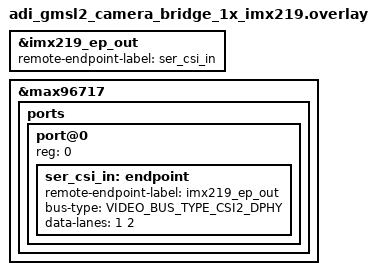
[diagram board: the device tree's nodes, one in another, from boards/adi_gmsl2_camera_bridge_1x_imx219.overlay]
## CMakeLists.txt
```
# SPDX-License-Identifier: Apache-2.0

cmake_minimum_required(VERSION 3.20.0)
find_package(Zephyr REQUIRED HINTS $ENV{ZEPHYR_BASE})
project(adi_gmsl2_camera_bridge)

target_sources(app PRIVATE
  src/main.c
  src/gmsl_diag.c
)
```

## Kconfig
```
# Copyright (c) 2026 Charles Dias
# SPDX-License-Identifier: Apache-2.0

mainmenu "GMSL2 Camera Bridge Sample"

source "Kconfig.zephyr"

module = APP
module-str = Application
source "subsys/logging/Kconfig.template.log_config"
```

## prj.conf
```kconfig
CONFIG_VIDEO=y
CONFIG_LOG=y
CONFIG_PRINTK=y
CONFIG_LOG_BUFFER_SIZE=8192

# CONFIG_VIDEO_FRAME_WIDTH=800
# CONFIG_VIDEO_FRAME_HEIGHT=480
# CONFIG_VIDEO_PIXEL_FORMAT="RGBP"
CONFIG_VIDEO_BUFFER_POOL_HEAP_SIZE=1600000
CONFIG_MAIN_STACK_SIZE=4096


# Remove before merging
CONFIG_APP_LOG_LEVEL_DBG=y
# CONFIG_VIDEO_LOG_LEVEL_DBG=y
```

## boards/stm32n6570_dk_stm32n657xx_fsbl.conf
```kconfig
# IMX219 through GMSL2 — capture + display
# DCMIPP source sensor format (IMX219 native)
CONFIG_VIDEO_STM32_DCMIPP_SENSOR_PIXEL_FORMAT="pBAA"
CONFIG_VIDEO_STM32_DCMIPP_SENSOR_WIDTH=3280
CONFIG_VIDEO_STM32_DCMIPP_SENSOR_HEIGHT=2464

# Deserializer in passthrough mode (not VPG)
CONFIG_VIDEO_MAX96724_VPG_INTERNAL=n
CONFIG_VIDEO_MAX96724_TPG_TOLERATE_NO_LINK=n

# An 800x480 RGB24 frame is 1152000 bytes; double-buffer + slack.
CONFIG_VIDEO_BUFFER_POOL_HEAP_SIZE=2500000

# Render frames on the on-board LTDC display.
CONFIG_DISPLAY=y
CONFIG_STM32_LTDC=y
CONFIG_STM32_LTDC_RGB888=y
```

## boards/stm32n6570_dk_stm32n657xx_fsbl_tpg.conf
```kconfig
# TPG validation mode: MAX96724 internal test pattern → CSI-2 → DCMIPP → display
CONFIG_APP_TPG_MODE=y

# Deserializer runs its own VPG — override the base board conf.
CONFIG_VIDEO_MAX96724_VPG_INTERNAL=y
CONFIG_VIDEO_MAX96724_TPG_TOLERATE_NO_LINK=y

# DCMIPP must be told to expect 800x480 RGB888 from its remote subdevice
# (the MAX96724 in VPG mode). Sized to fill the on-board LTDC panel.
CONFIG_VIDEO_STM32_DCMIPP_SENSOR_PIXEL_FORMAT="BGR3"
CONFIG_VIDEO_STM32_DCMIPP_SENSOR_WIDTH=800
CONFIG_VIDEO_STM32_DCMIPP_SENSOR_HEIGHT=480

# An 800x480 RGB24 frame is 1152000 bytes; double-buffer + slack.
CONFIG_VIDEO_BUFFER_POOL_HEAP_SIZE=2500000

# Render frames on the on-board LTDC display.
CONFIG_DISPLAY=y
CONFIG_STM32_LTDC=y

# The VPG produces RGB24, so size the LTDC framebuffer for 3 bytes/pixel.
# Without this the driver defaults to RGB565 (2 bytes/pixel) and the runtime
# display_set_pixel_format() switch overruns the back buffer.
CONFIG_STM32_LTDC_RGB888=y
```

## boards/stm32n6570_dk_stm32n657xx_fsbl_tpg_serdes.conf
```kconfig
# SerDes loopback validation: MAX96717 PATGEN -> GMSL2 -> MAX96724 passthrough
# -> CSI-2 -> DCMIPP -> display
CONFIG_APP_TPG_MODE=y

# DCMIPP must be told to expect 800x480 RGB888 from its remote subdevice.
CONFIG_VIDEO_STM32_DCMIPP_SENSOR_PIXEL_FORMAT="BGR3"
CONFIG_VIDEO_STM32_DCMIPP_SENSOR_WIDTH=800
CONFIG_VIDEO_STM32_DCMIPP_SENSOR_HEIGHT=480

# An 800x480 RGB24 frame is 1152000 bytes; double-buffer + slack.
CONFIG_VIDEO_BUFFER_POOL_HEAP_SIZE=2500000

# Render frames on the on-board LTDC display.
CONFIG_DISPLAY=y
CONFIG_STM32_LTDC=y
CONFIG_STM32_LTDC_RGB888=y

# Enable the serializer PATGEN as the frame source.
CONFIG_VIDEO_MAX96717=y
CONFIG_VIDEO_MAX96717_PATGEN_ENABLE=y
CONFIG_VIDEO_MAX96717_PATGEN_PATTERN_GRADIENT=y

# Deserializer runs in passthrough mode — no internal VPG.
CONFIG_VIDEO_MAX96724=y
CONFIG_VIDEO_MAX96724_VPG_INTERNAL=n

# The GMSL link must be locked — no tolerance for missing serializer.
CONFIG_VIDEO_MAX96724_TPG_TOLERATE_NO_LINK=n
```

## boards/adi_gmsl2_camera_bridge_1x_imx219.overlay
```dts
/*
 * Copyright (c) 2026 Charles Dias
 *
 * SPDX-License-Identifier: Apache-2.0
 *
 * Wires a single IMX219 camera sensor through the ADI GMSL2 bridge.
 *
 * Overlay merge order:
 *   1. raspberry_pi_camera_module_2 → creates IMX219, wires imx219_ep_out → csi_ep_in
 *   2. adi_gmsl2_camera_bridge      → creates MAX96724 + MAX96717, overrides csi_ep_in
 *   3. This overlay                 → rewires imx219_ep_out → max96717_csi_in
 *
 */

#include <zephyr/dt-bindings/video/video-interfaces.h>

&imx219_ep_out {
	remote-endpoint-label = "ser_csi_in";
};

&max96717 {
	ports {
		port@0 {
			reg = <0>;

			ser_csi_in: endpoint {
				remote-endpoint-label = "imx219_ep_out";
				bus-type = <VIDEO_BUS_TYPE_CSI2_DPHY>;
				data-lanes = <1 2>;
			};
		};
	};
};
```

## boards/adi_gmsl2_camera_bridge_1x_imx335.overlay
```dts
/*
 * Copyright (c) 2026 Charles Dias
 *
 * SPDX-License-Identifier: Apache-2.0
 *
 * Wires a single IMX335 camera sensor through the ADI GMSL2 bridge.
 *
 * Overlay merge order:
 *   1. st_b_cams_imx_mb1854 → creates IMX335, wires imx335_ep_out → csi_ep_in
 *   2. adi_gmsl2_camera_bridge      → creates MAX96724 + MAX96717, overrides csi_ep_in
 *   3. This overlay                 → rewires imx335_ep_out → max96717_csi_in
 *
 */

#include <zephyr/dt-bindings/video/video-interfaces.h>

&imx335_ep_out {
	remote-endpoint-label = "max96717_csi_in";
};

&max96717 {
	ports {
		port@0 {
			reg = <0>;

			max96717_csi_in: endpoint {
				remote-endpoint-label = "imx335_ep_out";
				bus-type = <VIDEO_BUS_TYPE_CSI2_DPHY>;
				data-lanes = <1 2>;
			};
		};
	};
};
```

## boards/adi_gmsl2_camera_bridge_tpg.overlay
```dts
/*
 * Copyright (c) 2026 Charles Dias
 *
 * SPDX-License-Identifier: Apache-2.0
 *
 * MAX96724 Video Pattern Generator (VPG / TPG) validation overlay.
 *
 * This overlay configures the sample to drive the host capture pipeline
 * (DCMIPP -> LTDC display) from the MAX96724's internal pattern generator,
 * with no GMSL link, no serializer, and no camera sensor in the loop.
 *
 * Use it together with the adi_gmsl2_camera_bridge shield (and *without*
 * any sensor shield):
 *
 *   west build -p -b stm32n6570_dk//fsbl \
 *     --shield adi_gmsl2_camera_bridge \
 *     samples/drivers/video/adi_gmsl2_camera_bridge \
 *     -- -DDTC_OVERLAY_FILE="boards/adi_gmsl2_camera_bridge_tpg.overlay" \
 *        -DEXTRA_CONF_FILE="boards/stm32n6570_dk_stm32n657xx_fsbl_tpg.conf"
 */

/ {
	chosen {
		zephyr,camera = &csi_capture_port;
	};
};

/* Enable the host DCMIPP/CSI capture interface — normally turned on by a
 * sensor shield, but in TPG mode the MAX96724 alone feeds the host link.
 */
&csi_interface {
	status = "okay";
};

/* No serializer present in TPG mode — disable to avoid probe errors. */
&max96717 {
	status = "disabled";
};
```

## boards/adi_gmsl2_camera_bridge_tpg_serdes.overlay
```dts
/*
 * Copyright (c) 2026 Charles Dias
 *
 * SPDX-License-Identifier: Apache-2.0
 *
 * MAX96717 SerDes Video Pattern Generator (VPG) validation overlay.
 *
 * This overlay validates the full SerDes path: the MAX96717 serializer's
 * internal PATGEN generates an 800x480 RGB888 frame, transmits it over
 * the GMSL2 link to the MAX96724 deserializer (running in passthrough
 * mode), which forwards it out MIPI CSI-2 to the host DCMIPP -> LTDC.
 *
 * Unlike the deserializer-only TPG overlay (_tpg.overlay), this variant
 * keeps the serializer enabled — PATGEN replaces the external sensor
 * input internally, so no camera module is needed on the serializer side.
 * The GMSL coax cable must be connected.
 *
 *   west build -p -b stm32n6570_dk//fsbl \
 *     --shield adi_gmsl2_camera_bridge \
 *     samples/drivers/video/adi_gmsl2_camera_bridge \
 *     -- -DDTC_OVERLAY_FILE="boards/adi_gmsl2_camera_bridge_tpg_serdes.overlay" \
 *        -DEXTRA_CONF_FILE="boards/stm32n6570_dk_stm32n657xx_fsbl_tpg_serdes.conf"
 */

/ {
	chosen {
		zephyr,camera = &csi_capture_port;
	};
};

/* Enable the host DCMIPP/CSI capture interface. */
&csi_interface {
	status = "okay";
};

/*
 * Keep the serializer enabled — PATGEN drives pipe 0 internally,
 * no parallel sensor on max96717 port@0 is needed.
 */
```

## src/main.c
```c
/*
 * Copyright (c) 2026 Charles Dias
 *
 * SPDX-License-Identifier: Apache-2.0
 */

#include <zephyr/device.h>
#include <zephyr/drivers/video.h>
#include <zephyr/drivers/video-controls.h>
#include <zephyr/kernel.h>
#include <zephyr/logging/log.h>

#if IS_ENABLED(CONFIG_DISPLAY)
#include <zephyr/drivers/display.h>
#endif

LOG_MODULE_REGISTER(main, CONFIG_APP_LOG_LEVEL);

#if !DT_HAS_CHOSEN(zephyr_camera)
#error No camera chosen in devicetree.
#endif

#define CAMERA_DEV DEVICE_DT_GET(DT_CHOSEN(zephyr_camera))

#define CAPTURE_NUM_BUFS  2
#define CAPTURE_LOG_EVERY 60

#if IS_ENABLED(CONFIG_DISPLAY)

/*
 * Clear the LCD once at startup. The LTDC framebuffer lives in PSRAM and is
 * not zero-initialised, so the area outside the capture region would otherwise
 * show stale content from a previous run.
 */
static void clear_display(const struct device *display_dev,
			   const struct display_capabilities *caps)
{
	static uint8_t black_line[800 * 3];
	struct display_buffer_descriptor desc = {
		.buf_size = sizeof(black_line),
		.width = caps->x_resolution,
		.pitch = caps->x_resolution,
		.height = 1,
	};

	for (uint16_t y = 0; y < caps->y_resolution; y++) {
		(void)display_write(display_dev, 0, y, &desc, black_line);
	}
}

static int setup_display(const struct device *display_dev, uint32_t pixfmt)
{
	struct display_capabilities caps;
	int ret = 0;

	if (!device_is_ready(display_dev)) {
		LOG_ERR("Display %s not ready", display_dev->name);
		return -ENODEV;
	}

	display_get_capabilities(display_dev, &caps);
	LOG_INF("Display %s: %ux%u, current pixfmt=%u", display_dev->name, caps.x_resolution,
		caps.y_resolution, caps.current_pixel_format);

	if ((pixfmt == VIDEO_PIX_FMT_RGB24 || pixfmt == VIDEO_PIX_FMT_BGR24) &&
	    caps.current_pixel_format != PIXEL_FORMAT_RGB_888) {
		ret = display_set_pixel_format(display_dev, PIXEL_FORMAT_RGB_888);
		if (ret < 0) {
			LOG_WRN("Display does not accept RGB_888 (err %d) — frames will still be"
				" logged",
				ret);
		} else {
			display_get_capabilities(display_dev, &caps);
		}
	}

	clear_display(display_dev, &caps);

	ret = display_blanking_off(display_dev);
	if (ret == -ENOSYS) {
		ret = 0;
	}
	return ret;
}

static void display_frame(const struct device *display_dev, const struct video_buffer *vbuf,
			   const struct video_format *fmt)
{
	struct display_buffer_descriptor desc = {
		.buf_size = vbuf->bytesused,
		.width = fmt->width,
		.pitch = fmt->width,
		.height = vbuf->bytesused / fmt->pitch,
	};

	(void)display_write(display_dev, 0, vbuf->line_offset, &desc, vbuf->buffer);
}

#endif /* CONFIG_DISPLAY */

int main(void)
{
	const struct device *camera = CAMERA_DEV;
	struct video_format fmt = {.type = VIDEO_BUF_TYPE_OUTPUT};
	struct video_buffer *vbuf;
	unsigned int frame = 0;
	uint32_t last_ts = 0;
	int ret;

#if IS_ENABLED(CONFIG_DISPLAY)
	const struct device *display = DEVICE_DT_GET_OR_NULL(DT_CHOSEN(zephyr_display));
#endif

	if (IS_ENABLED(CONFIG_APP_TPG_MODE)) {
		LOG_INF("MAX96724 VPG (TPG) validation start");
	} else {
		LOG_INF("GMSL2 camera bridge — capture start");
	}

	if (!device_is_ready(camera)) {
		LOG_ERR("Camera %s not ready", camera->name);
		return -ENODEV;
	}

	/*
	 * Set up the capture format.
	 * In TPG mode: hard-code 800x480 BGR24 (the VPG's only output).
	 * In camera mode: use 800x480 BGR24 to match the LTDC panel.
	 */
	fmt.pixelformat = VIDEO_PIX_FMT_BGR24;
	fmt.width = 800;
	fmt.height = 480;
	fmt.pitch = fmt.width * 3U;
	fmt.size = fmt.pitch * fmt.height;

	ret = video_set_compose_format(camera, &fmt);
	if (ret < 0) {
		LOG_ERR("video_set_compose_format failed (err %d)", ret);
		return ret;
	}

	ret = video_get_format(camera, &fmt);
	if (ret < 0) {
		LOG_ERR("video_get_format (post set) failed (err %d)", ret);
		return ret;
	}

	LOG_INF("Format: %s %ux%u (pitch %u, size %u)", VIDEO_FOURCC_TO_STR(fmt.pixelformat),
		fmt.width, fmt.height, fmt.pitch, fmt.size);

	if (fmt.size == 0U) {
		LOG_ERR("DCMIPP returned size=0 — pipe format not configured");
		return -EINVAL;
	}

	/* Enable test pattern on the sensor if requested via Kconfig */
	if (CONFIG_APP_TEST_PATTERN > 0) {
		struct video_control ctrl = {
			.id = VIDEO_CID_TEST_PATTERN,
			.val = CONFIG_APP_TEST_PATTERN,
		};

		ret = video_set_ctrl(camera, &ctrl);
		if (ret < 0 && ret != -ENOTSUP) {
			LOG_WRN("Failed to set test pattern %d (err %d)",
				CONFIG_APP_TEST_PATTERN, ret);
		} else if (ret == 0) {
			LOG_INF("Test pattern %d enabled", CONFIG_APP_TEST_PATTERN);
		}
	}

#if IS_ENABLED(CONFIG_DISPLAY)
	if (display != NULL) {
		ret = setup_display(display, fmt.pixelformat);
		if (ret < 0) {
			LOG_WRN("Display setup failed (err %d) — continuing headless", ret);
			display = NULL;
		}
	} else {
		LOG_INF("No zephyr,display chosen — running headless");
	}
#endif

	for (int i = 0; i < CAPTURE_NUM_BUFS; i++) {
		vbuf = video_buffer_aligned_alloc(fmt.size, CONFIG_VIDEO_BUFFER_POOL_ALIGN,
						  K_NO_WAIT);
		if (vbuf == NULL) {
			LOG_ERR("Failed to alloc video buffer %d", i);
			return -ENOMEM;
		}
		vbuf->type = VIDEO_BUF_TYPE_OUTPUT;
		ret = video_enqueue(camera, vbuf);
		if (ret < 0) {
			LOG_ERR("video_enqueue failed (err %d)", ret);
			return ret;
		}
	}

	ret = video_stream_start(camera, VIDEO_BUF_TYPE_OUTPUT);
	if (ret < 0) {
		LOG_ERR("video_stream_start failed (err %d)", ret);
		return ret;
	}

	LOG_INF("Capture started");

	vbuf = NULL;
	while (1) {
		ret = video_dequeue(camera, &vbuf, K_MSEC(2000));
		if (ret == -EAGAIN) {
			LOG_WRN("video_dequeue timed out — DCMIPP not delivering frames");
			continue;
		}
		if (ret < 0) {
			LOG_ERR("video_dequeue failed (err %d)", ret);
			return ret;
		}

		if ((frame % CAPTURE_LOG_EVERY) == 0) {
			LOG_INF("Frame %u: %u bytes, ts=%u ms (delta %u ms)", frame,
				vbuf->bytesused, vbuf->timestamp, vbuf->timestamp - last_ts);
		}
		frame++;
		last_ts = vbuf->timestamp;

#if IS_ENABLED(CONFIG_DISPLAY)
		if (display != NULL) {
			display_frame(display, vbuf, &fmt);
		}
#endif

		ret = video_enqueue(camera, vbuf);
		if (ret < 0) {
			LOG_ERR("video_enqueue (requeue) failed (err %d)", ret);
			return ret;
		}
	}
}
```

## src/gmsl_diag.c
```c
/*
 * Copyright (c) 2026 Charles Dias
 *
 * SPDX-License-Identifier: Apache-2.0
 */

#include "gmsl_diag.h"

#include <zephyr/drivers/i2c.h>
#include <zephyr/logging/log.h>

LOG_MODULE_REGISTER(gmsl_diag, CONFIG_APP_LOG_LEVEL);

/* Device I2C addresses (7-bit) */
#define MAX96724_I2C_ADDR           DT_REG_ADDR(DT_NODELABEL(max96724))
#define MAX96717_I2C_ADDR           DT_REG_ADDR(DT_NODELABEL(max96717))
#define IMX219_I2C_ADDR             DT_REG_ADDR(DT_NODELABEL(imx219))

/* Chip ID register addresses (16-bit) and expected values */
#define MAX96724_REG_DEVID          0x000D
#define MAX96717_REG_DEVID          0x000D
#define IMX219_REG_DEVID            0x0000
#define IMX219_DEVID_EXPECT         0x0219

static const char *max96724_variant_model(uint8_t id)
{
	switch (id) {
	case 0xA2:
		return "MAX96724";
	case 0xA3:
		return "MAX96724F";
	case 0xA4:
		return "MAX96724R";
	default:
		return "unknown";
	}
}

static const char *max96717_variant_model(uint8_t id)
{
	switch (id) {
	case 0xBF:
		return "MAX96717";
	default:
		return "unknown";
	}
}

void i2c_scan_devices(const struct device *i2c_dev)
{
	struct i2c_msg msg;
	uint8_t buffer;
	int found = 0;

	msg.buf = &buffer;
	msg.len = 0U;
	msg.flags = I2C_MSG_WRITE | I2C_MSG_STOP;

	LOG_DBG("--- Scanning I2C bus %s ---", i2c_dev->name);

	for (uint8_t addr = 0x04; addr <= 0x77; addr++) {
		if (i2c_transfer(i2c_dev, &msg, 1, addr) == 0) {
			LOG_DBG("  Found device at 0x%02X", addr);
			found++;
		}
	}

	LOG_DBG("Scan complete: %d device(s) found", found);
}

static int check_device_id(const struct device *i2c_dev, const char *name, uint8_t addr,
			   uint16_t reg, uint8_t *id, uint8_t len)
{
	uint8_t reg_buf[2] = {reg >> 8, reg & 0xFF};
	int ret;

	ret = i2c_write_read(i2c_dev, addr, reg_buf, sizeof(reg_buf), id, len);
	if (ret < 0) {
		LOG_ERR("%s (0x%02x): not reachable (err %d)", name, addr, ret);
		return ret;
	}

	if (len == 1) {
		LOG_DBG("%s (0x%02X): ID = 0x%02X", name, addr, id[0]);
	} else {
		LOG_DBG("%s (0x%02X): ID = 0x%02X 0x%02X", name, addr, id[0], id[1]);
	}

	return 0;
}

void verify_device_ids(const struct device *i2c_dev)
{
	uint8_t id[2];

	LOG_DBG("--- Device ID check ---");

	check_device_id(i2c_dev, "MAX96724", MAX96724_I2C_ADDR, MAX96724_REG_DEVID, id, 1);
	LOG_DBG("  Model: %s (ID=0x%02X)", max96724_variant_model(id[0]), id[0]);

	check_device_id(i2c_dev, "MAX96717", MAX96717_I2C_ADDR, MAX96717_REG_DEVID, id, 1);
	LOG_DBG("  Model: %s (ID=0x%02X)", max96717_variant_model(id[0]), id[0]);

	check_device_id(i2c_dev, "IMX219", IMX219_I2C_ADDR, IMX219_REG_DEVID, id, 2);
	if (((uint16_t)id[0] << 8 | id[1]) != IMX219_DEVID_EXPECT) {
		LOG_WRN("  Expected 0x%04X, got 0x%02X%02X", IMX219_DEVID_EXPECT, id[0], id[1]);
	}
}
```

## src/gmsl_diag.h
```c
/*
 * Copyright (c) 2026 Charles Dias
 *
 * SPDX-License-Identifier: Apache-2.0
 */

#ifndef GMSL_DIAG_H
#define GMSL_DIAG_H

#include <zephyr/device.h>

void i2c_scan_devices(const struct device *i2c_dev);
void verify_device_ids(const struct device *i2c_dev);

#endif /* GMSL_DIAG_H */
```
